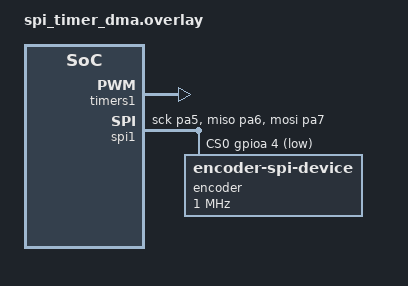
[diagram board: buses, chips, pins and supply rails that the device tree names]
/*
 * Device tree example for STM32 SPI Timer-Triggered DMA configuration
 * 
 * This example shows how to configure SPI with timer-triggered DMA
 * for FOC motor control applications.
 */

/ {
	aliases {
		spi-encoder = &spi1;
		pwm-motor = &pwm1;
	};
};

/* PWM Timer configuration for motor control */
&timers1 {
	status = "okay";
	
	pwm1: pwm {
		status = "okay";
		pinctrl-0 = <&tim1_ch1_pe9 &tim1_ch2_pe11 &tim1_ch3_pe13>;
		pinctrl-names = "default";
		/* PWM generates 3-phase motor control signals */
		/* Timer update event triggers SPI DMA for encoder reading */
	};
};

/* SPI configuration for encoder reading with timer-triggered DMA */
&spi1 {
	status = "okay";
	pinctrl-0 = <&spi1_sck_pa5 &spi1_miso_pa6 &spi1_mosi_pa7>;
	pinctrl-names = "default";
	
	/*
	 * Key difference: DMA trigger source is timer instead of SPI
	 * Normal SPI would use: dmas = <&dma2 2 SPI1_RX>;
	 * Timer-triggered uses: dmas = <&dma2 2 TIM1_UP>;
	 */
	dmas = <&dma2 2 TIM1_UP>;
	dma-names = "rx";
	
	/* SPI configuration for encoder communication */
	cs-gpios = <&gpioa 4 GPIO_ACTIVE_LOW>;
	
	encoder@0 {
		compatible = "encoder-spi-device";
		reg = <0>;
		spi-max-frequency = <1000000>; /* 1 MHz */
		/* Encoder-specific properties */
	};
};

/* DMA controller configuration */
&dma2 {
	status = "okay";
};

/*
 * Example board overlay for different STM32 variants:
 * 
 * STM32F4:
 * &spi1 {
 *     dmas = <&dma2 2 0 (STM32_DMA_PERIPH_TX | STM32_DMA_PRIORITY_HIGH)>,
 *            <&dma2 0 3 (STM32_DMA_PERIPH_RX | STM32_DMA_PRIORITY_HIGH)>;
 *     dma-names = "tx", "rx";
 * };
 * 
 * STM32H7:
 * &spi1 {
 *     dmas = <&dmamux1 38 107 (STM32_DMA_PERIPH_TX | STM32_DMA_PRIORITY_HIGH)>,
 *            <&dmamux1 37 106 (STM32_DMA_PERIPH_RX | STM32_DMA_PRIORITY_HIGH)>;
 *     dma-names = "tx", "rx";
 * };
 */

/*
 * Application configuration:
 */
/ {
	foc_config {
		/* PWM frequency for motor control */
		pwm-frequency = <20000>; /* 20 kHz */
		
		/* Encoder reading synchronized with PWM */
		encoder-reads-per-pwm-cycle = <1>;
		
		/* Buffer size for circular DMA */
		encoder-buffer-size = <128>;
	};
};
